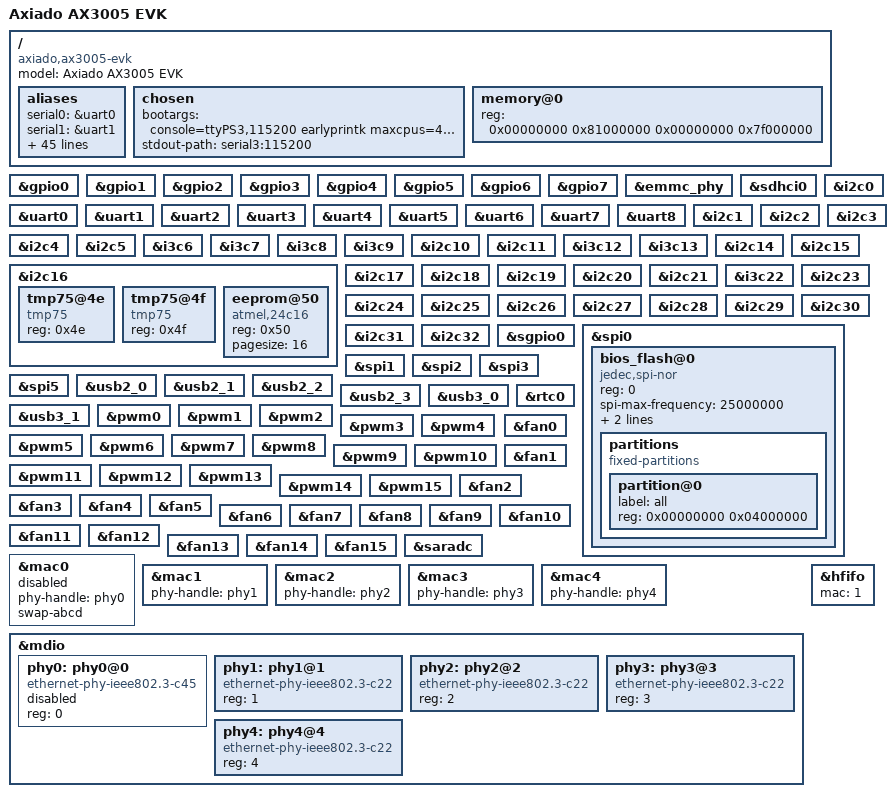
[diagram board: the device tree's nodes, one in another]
// SPDX-License-Identifier: GPL-2.0+
/*
 * DTS file for Axiado AX3005 SoC based EVK
 * Copyright (c) 2026 Axiado Corporation
 */

/dts-v1/;

#include "ax3005.dtsi"

/ {
	model = "Axiado AX3005 EVK";
	compatible = "axiado,ax3005-evk", "axiado,ax3005";
	#address-cells = <2>;
	#size-cells = <2>;

	aliases {
		serial0 = &uart0;
		serial1 = &uart1;
		serial2 = &uart2;
		serial3 = &uart3;
		serial4 = &uart4;
		serial5 = &uart5;
		serial6 = &uart6;
		serial7 = &uart7;
		serial8 = &uart8;
		i2c0 = &i2c0;
		i2c1 = &i2c1;
		i2c2 = &i2c2;
		i2c3 = &i2c3;
		i2c4 = &i2c4;
		i2c5 = &i2c5;
		i2c6 = &i3c6;
		i2c7 = &i3c7;
		i2c8 = &i3c8;
		i2c9 = &i3c9;
		i2c10 = &i2c10;
		i2c11 = &i2c11;
		i2c12 = &i3c12;
		i2c13 = &i3c13;
		i2c14 = &i2c14;
		i2c15 = &i2c15;
		i2c16 = &i2c16;
		i2c17 = &i2c17;
		i2c18 = &i2c18;
		i2c19 = &i2c19;
		i2c20 = &i2c20;
		i2c21 = &i2c21;
		i2c22 = &i3c22;
		i2c23 = &i2c23;
		i2c24 = &i2c24;
		i2c25 = &i2c25;
		i2c26 = &i2c26;
		i2c27 = &i2c27;
		i2c28 = &i2c28;
		i2c29 = &i2c29;
		i2c30 = &i2c30;
		i2c31 = &i2c31;
		spi0  = &spi0;
		spi1  = &spi1;
		spi2  = &spi2;
		spi3  = &spi3;
		spi5  = &spi5;
		spi6  = &spi6;
	};

	chosen {
		bootargs = "console=ttyPS3,115200 earlyprintk maxcpus=4 nr_cpus=4 earlycon";
		stdout-path = "serial3:115200";
	};

	memory@0 {
		device_type = "memory";
		/* Cortex-A53 will use following memory map */
		reg = <0x00000000 0x81000000 0x00000000 0x7f000000>;
	};
};

&gpio0 {
	status = "okay";
};

&gpio1 {
	status = "okay";
};

&gpio2 {
	status = "okay";
};

&gpio3 {
	status = "okay";
};

&gpio4 {
	status = "okay";
};

&gpio5 {
	status = "okay";
};

&gpio6 {
	status = "okay";
};

&gpio7 {
	status = "okay";
};

&emmc_phy {
	status = "okay";
};

&sdhci0 {
	status = "okay";
};

&uart0 {
	status = "okay";
};

&uart1 {
	status = "okay";
};

&uart2 {
	status = "okay";
};

&uart3 {
	status = "okay";
};

&uart4 {
	status = "okay";
};

&uart5 {
	status = "okay";
};

&uart6 {
	status = "okay";
};

&uart7 {
	status = "okay";
};

&uart8 {
	status = "okay";
};

&i2c0 {
	status = "okay";
};

&i2c1 {
	status = "okay";
};

&i2c2 {
	status = "okay";
};

&i2c3 {
	status = "okay";
};

&i2c4 {
	status = "okay";
};

&i2c5 {
	status = "okay";
};

&i3c6 {
	status = "okay";
};

&i3c7 {
	status = "okay";
};

&i3c8 {
	status = "okay";
};

&i3c9 {
	status = "okay";
};

&i2c10 {
	status = "okay";
};

&i2c11 {
	status = "okay";
};

&i3c12 {
	status = "okay";
};

&i3c13 {
	status = "okay";
};

&i2c14 {
	status = "okay";
};

&i2c15 {
	status = "okay";
};

&i2c16 {
	status = "okay";
	#address-cells = <1>;
	tmp75@4e {
		compatible = "tmp75";
		reg = <0x4e>;
		status = "okay";
	};
	tmp75@4f {
		compatible = "tmp75";
		reg = <0x4f>;
		status = "okay";
	};
	eeprom@50 {
		compatible = "atmel,24c16";
		reg = <0x50>;
		pagesize = <16>;
		status = "okay";
	};
};

&i2c17 {
	status = "okay";
};

&i2c18 {
	status = "okay";
};

&i2c19 {
	status = "okay";
};

&i2c20 {
	status = "okay";
};

&i2c21 {
	status = "okay";
};

&i3c22 {
	status = "okay";
};

&i2c23 {
	status = "okay";
};

&i2c24 {
	status = "okay";
};

&i2c25 {
	status = "okay";
};

&i2c26 {
	status = "okay";
};

&i2c27 {
	status = "okay";
};

&i2c28 {
	status = "okay";
};

&i2c29 {
	status = "okay";
};

&i2c30 {
	status = "okay";
};

&i2c31 {
	status = "okay";
};

&i2c32 {
	status = "okay";
};

&sgpio0 {
	status = "okay";
};

&spi0 {
	status = "okay";
	bios_flash@0 {
		status = "okay";
		compatible = "jedec,spi-nor";
		reg = <0>;
		spi-max-frequency = <25000000>;
		spi-rx-bus-width = <4>;
		spi-tx-bus-width = <4>;
		#address-cells = <1>;
		#size-cells = <1>;

		partitions {
			compatible = "fixed-partitions";
			#address-cells = <1>;
			#size-cells = <1>;

			partition@0 {
				label = "all";
				reg = <0x00000000 0x04000000>; // 64MB
			};
		};
	};
};

&spi1 {
	status = "okay";
};

&spi2 {
	status = "okay";
};

&spi3 {
	status = "okay";
};

&spi5 {
	status = "okay";
};

&usb2_0 {
	status = "okay";
};

&usb2_1 {
	status = "okay";
};

&usb2_2 {
	status = "okay";
};

&usb2_3 {
	status = "okay";
};

&usb3_0 {
	status = "okay";
};

&usb3_1 {
	status = "okay";
};

&rtc0 {
	status = "okay";
};

&pwm0 {
	status = "okay";
};

&pwm1 {
	status = "okay";
};

&pwm2 {
	status = "okay";
};

&pwm3 {
	status = "okay";
};

&pwm4 {
	status = "okay";
};

&pwm5 {
	status = "okay";
};

&pwm6 {
	status = "okay";
};

&pwm7 {
	status = "okay";
};

&pwm8 {
	status = "okay";
};

&pwm9 {
	status = "okay";
};

&pwm10 {
	status = "okay";
};

&pwm11 {
	status = "okay";
};

&pwm12 {
	status = "okay";
};

&pwm13 {
	status = "okay";
};

&pwm14 {
	status = "okay";
};

&pwm15 {
	status = "okay";
};

&fan0 {
	status = "okay";
};

&fan1{
	status = "okay";
};

&fan2 {
	status = "okay";
};

&fan3 {
	status = "okay";
};

&fan4 {
	status = "okay";
};

&fan5 {
	status = "okay";
};

&fan6 {
	status = "okay";
};

&fan7 {
	status = "okay";
};

&fan8 {
	status = "okay";
};

&fan9 {
	status = "okay";
};

&fan10 {
	status = "okay";
};

&fan11 {
	status = "okay";
};

&fan12 {
	status = "okay";
};

&fan13 {
	status = "okay";
};

&fan14 {
	status = "okay";
};

&fan15 {
	status = "okay";
};

&saradc {
	status = "okay";
};

&mac0 {
	phy-handle = <&phy0>;
	swap-abcd;
	status = "disabled";
};

&mac1 {
	phy-handle = <&phy1>;
	status = "okay";
};

&mac2 {
	phy-handle = <&phy2>;
	status = "okay";
};

&mac3 {
	phy-handle = <&phy3>;
	status = "okay";
};

&mac4 {
	phy-handle = <&phy4>;
	status = "okay";
};

&mdio {
	phy0: phy0@0 {
		reg = <0>;
		compatible = "ethernet-phy-ieee802.3-c45";
		#thermal-sensor-cells = <0>;
		status = "disabled";
	};
	phy1: phy1@1 {
		reg = <1>;
		compatible = "ethernet-phy-ieee802.3-c22";
		#thermal-sensor-cells = <0>;
		status = "okay";
	};
	phy2: phy2@2 {
		reg = <2>;
		compatible = "ethernet-phy-ieee802.3-c22";
		#thermal-sensor-cells = <0>;
		status = "okay";
	};
	phy3: phy3@3 {
		reg = <3>;
		compatible = "ethernet-phy-ieee802.3-c22";
		#thermal-sensor-cells = <0>;
		status = "okay";
	};
	phy4: phy4@4 {
		reg = <4>;
		compatible = "ethernet-phy-ieee802.3-c22";
		#thermal-sensor-cells = <0>;
		status = "okay";
	};
};

&hfifo {
	mac = <1>;
	status = "okay";
};
